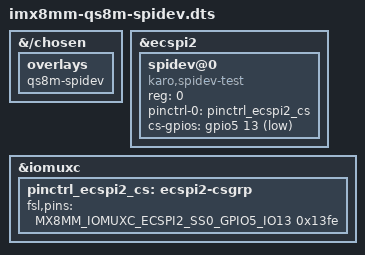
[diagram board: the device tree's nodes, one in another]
// SPDX-License-Identifier: (GPL-2.0 OR BSD-3-Clause)
/*
 * Copyright (C) 2023 Lothar Waßmann <LW@KARO-electronics.de>
 */

/dts-v1/;

/plugin/;

#include <dt-bindings/gpio/gpio.h>
#include "imx8mm-pinfunc.h"

&{/chosen} {
	overlays {
		qs8m-spidev;
	};
};

&ecspi2 {
	status = "okay";

	spidev@0 {
		reg = <0>;
		compatible = "karo,spidev-test";
		pinctrl-names = "default";
		pinctrl-0 = <&pinctrl_ecspi2_cs>;
		cs-gpios = <&gpio5 13 GPIO_ACTIVE_LOW>;
	};
};

&iomuxc {
	pinctrl_ecspi2_cs: ecspi2-csgrp {
		fsl,pins = <
			MX8MM_IOMUXC_ECSPI2_SS0_GPIO5_IO13		0x13fe
		>;
	};
};
